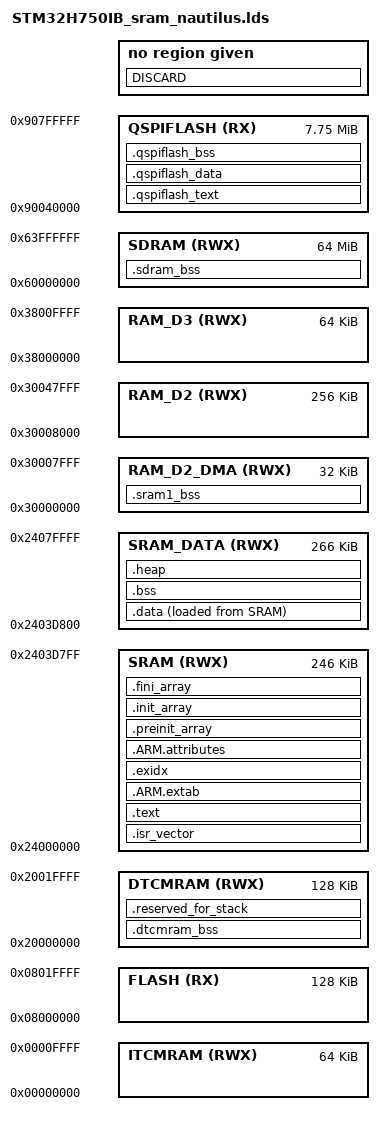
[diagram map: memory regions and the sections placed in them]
/* Nautilus: copy of libDaisy v7.1.0 core/STM32H750IB_sram.lds, with the changes shown
   by the Reset_Handler and _sbrk literals in Nautilus_v1_2_0-wht3.bin:
   - .data (VMA 0x2403d800, copied from the end of the code) and .bss (0x2403dc18-0x2407d824)
     go in SRAM (AXI), not DTCM: the .bss (~256 KB) does not fit in the 128 KB of DTCM.
     The 0x2403d800 origin comes from the binary; nothing was found that uses the ~60 KB
     between the end of the code and .data. The SRAM_DATA region reaches the end of AXI SRAM.
   - No BACKUP_SRAM region (as before libDaisy v6): .backup_sram (boot_info, 12 bytes)
     is orphaned and ld places it after .data (0x2403dc0c, with its copy in the image).
   - The heap (end) starts at the end of .bss (0x2407d824), not in RAM_D2.
   SDRAM at 0x60000000: the patched libDaisy swaps the FMC banks (sdram.cpp). */
/* Generated by LinkerScriptGenerator [http://visualgdb.com/tools/LinkerScriptGenerator]
 * Target: STM32H750IB
 * The file is provided under the BSD license.
 */

ENTRY(Reset_Handler)

MEMORY
{
	FLASH       (RX)  : ORIGIN = 0x08000000, LENGTH = 128K
	DTCMRAM     (RWX) : ORIGIN = 0x20000000, LENGTH = 128K
	SRAM        (RWX) : ORIGIN = 0x24000000, LENGTH = 0x3d800
	SRAM_DATA   (RWX) : ORIGIN = 0x2403d800, LENGTH = 512K - 0x3d800 /* Nautilus */
	RAM_D2_DMA  (RWX) : ORIGIN = 0x30000000, LENGTH = 32K
	RAM_D2      (RWX) : ORIGIN = 0x30008000, LENGTH = 256K
	RAM_D3      (RWX) : ORIGIN = 0x38000000, LENGTH = 64K
	ITCMRAM     (RWX) : ORIGIN = 0x00000000, LENGTH = 64K
	SDRAM       (RWX) : ORIGIN = 0x60000000, LENGTH = 64M /* Nautilus: FMC_SWAPBMAP_SDRAM_SRAM */
	QSPIFLASH   (RX)  : ORIGIN = 0x90040000, LENGTH = 7936K
}

_estack = 0x20020000;

SECTIONS
{
	.isr_vector :
	{
		. = ALIGN(4);
		KEEP(*(.isr_vector))
		. = ALIGN(4);
	} > SRAM

	.text :
	{
		. = ALIGN(4);
		_stext = .;

		*(.text)
		*(.text*)
		*(.rodata)
		*(.rodata*)
		*(.glue_7)
		*(.glue_7t)
		KEEP(*(.init))
		KEEP(*(.fini))
		. = ALIGN(4);
		_etext = .;

	} > SRAM

	.ARM.extab :
	{
		. = ALIGN(4);
		*(.ARM.extab)
		*(.gnu.linkonce.armextab.*)
		. = ALIGN(4);
	} > SRAM

	.exidx :
	{
		. = ALIGN(4);
		PROVIDE(__exidx_start = .);
		*(.ARM.exidx*)
		. = ALIGN(4);
		PROVIDE(__exidx_end = .);
	} > SRAM

	.ARM.attributes :
	{
		*(.ARM.attributes)
	} > SRAM

	.preinit_array :
	{
		PROVIDE(__preinit_array_start = .);
		KEEP(*(.preinit_array*))
		PROVIDE(__preinit_array_end = .);
	} > SRAM

	.init_array :
	{
		PROVIDE(__init_array_start = .);
		KEEP(*(SORT(.init_array.*)))
		KEEP(*(.init_array*))
		PROVIDE(__init_array_end = .);
	} > SRAM

	.fini_array :
	{
		PROVIDE(__fini_array_start = .);
		KEEP(*(.fini_array*))
		KEEP(*(SORT(.fini_array.*)))
		PROVIDE(__fini_array_end = .);
	} > SRAM

	.sram1_bss (NOLOAD) :
	{
		. = ALIGN(4);
		_ssram1_bss = .;

		PROVIDE(__sram1_bss_start__ = _sram1_bss);
		*(.sram1_bss)
		*(.sram1_bss*)
		. = ALIGN(4);
		_esram1_bss = .;

		PROVIDE(__sram1_bss_end__ = _esram1_bss);
	} > RAM_D2_DMA

	.data :
	{
		. = ALIGN(4);
		_sdata = .;

		PROVIDE(__data_start__ = _sdata);
		*(.data)
		*(.data*)
		. = ALIGN(4);
		_edata = .;

		PROVIDE(__data_end__ = _edata);
	} > SRAM_DATA AT > SRAM

	_sidata = LOADADDR(.data);

	.bss (NOLOAD) :
	{
		. = ALIGN(4);
		_sbss = .;

		PROVIDE(__bss_start__ = _sbss);
		*(.bss)
		*(.bss*)
		*(COMMON)
		. = ALIGN(4);
		_ebss = .;

		PROVIDE(__bss_end__ = _ebss);
	} > SRAM_DATA

	.dtcmram_bss (NOLOAD) :
	{
		. = ALIGN(4);
		_sdtcmram_bss = .;

		PROVIDE(__dtcmram_bss_start__ = _sdtcmram_bss);
		*(.dtcmram_bss)
		*(.dtcmram_bss*)
		. = ALIGN(4);
		_edtcmram_bss = .;

		PROVIDE(__dtcmram_bss_end__ = _edtcmram_bss);
	} > DTCMRAM

	/*
	.sdram_text :
	{
		. = ALIGN(4);
		_ssdram_text = .;

		PROVIDE(__sdram_text_start = _ssdram_text);
		*(.sdram_text)
		*(.sdram_text*)
		. = ALIGN(4);
		_esdram_text = .;

		PROVIDE(__sdram_text_end = _esdram_text);
	} > SDRAM AT >FLASH
	_sisdram_text = LOADADDR(.sdram_text);
	*/

	.sdram_bss (NOLOAD) :
	{
		. = ALIGN(4);
		_ssdram_bss = .;

		PROVIDE(__sdram_bss_start = _ssdram_bss);
		*(.sdram_bss)
		*(.sdram_bss*)
		. = ALIGN(4);
		_esdram_bss = .;

		PROVIDE(__sdram_bss_end = _esdram_bss);
	} > SDRAM

	.qspiflash_text :
	{
		. = ALIGN(4);
		_sqspiflash_text = .;

		PROVIDE(__qspiflash_text_start = _sqspiflash_text);
		*(.qspiflash_text)
		*(.qspiflash_text*)
		. = ALIGN(4);
		_eqspiflash_text = .;

		PROVIDE(__qspiflash_text_end = _eqspiflash_text);
	} > QSPIFLASH

	.qspiflash_data :
	{
		. = ALIGN(4);
		_sqspiflash_data = .;

		PROVIDE(__qspiflash_data_start = _sqspiflash_data);
		*(.qspiflash_data)
		*(.qspiflash_data*)
		. = ALIGN(4);
		_eqspiflash_data = .;

		PROVIDE(__qspiflash_data_end = _eqspiflash_data);
	} > QSPIFLASH

	.qspiflash_bss (NOLOAD) :
	{
		. = ALIGN(4);
		_sqspiflash_bss = .;

		PROVIDE(__qspiflash_bss_start = _sqspiflash_bss);
		*(.qspiflash_bss)
		*(.qspiflash_bss*)
		. = ALIGN(4);
		_eqspiflash_bss = .;

		PROVIDE(__qspiflash_bss_end = _eqspiflash_bss);
	} > QSPIFLASH

	.heap (NOLOAD) :
	{
		. = ALIGN(4);
		PROVIDE(__heap_start__ = .);
		KEEP(*(.heap))
		. = ALIGN(4);
		PROVIDE(__heap_end__ = .);
	} > SRAM_DATA

	PROVIDE(end = .);

	.reserved_for_stack (NOLOAD) :
	{
		. = ALIGN(4);
		PROVIDE(__reserved_for_stack_start__ = .);
		KEEP(*(.reserved_for_stack))
		. = ALIGN(4);
		PROVIDE(__reserved_for_stack_end__ = .);
	} > DTCMRAM

    DISCARD :
    {
        libc.a ( * )
        libm.a ( * )
        libgcc.a ( * )
    }

}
